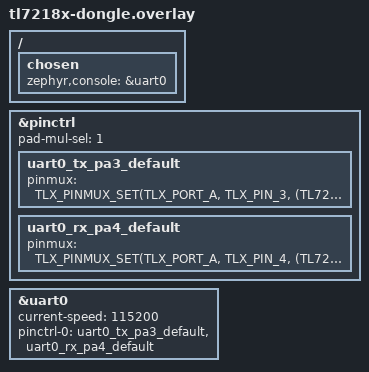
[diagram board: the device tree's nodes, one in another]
/*
 * Copyright (c) 2024 Telink Semiconductor
 *
 * SPDX-License-Identifier: Apache-2.0
 */

#include <zephyr/dt-bindings/pinctrl/tl721x-pinctrl.h>

/ {
	chosen {
		zephyr,console = &uart0;
	};
};

&pinctrl {
	pad-mul-sel = <1>;

	uart0_tx_pa3_default: uart0_tx_pa3_default {
		pinmux = <TLX_PINMUX_SET(TLX_PORT_A, TLX_PIN_3, (TL721X_FUNC_UART0_TX | TL721X_PULL_UP))>;
	};
	uart0_rx_pa4_default: uart0_rx_pa4_default {
		pinmux = <TLX_PINMUX_SET(TLX_PORT_A, TLX_PIN_4, (TL721X_FUNC_UART0_RTX_IO | TL721X_PULL_UP))>;
	};
};

&uart0 {
	status = "okay";
	current-speed = <115200>;
	pinctrl-0 = <&uart0_tx_pa3_default &uart0_rx_pa4_default>;
	pinctrl-names = "default";
};
